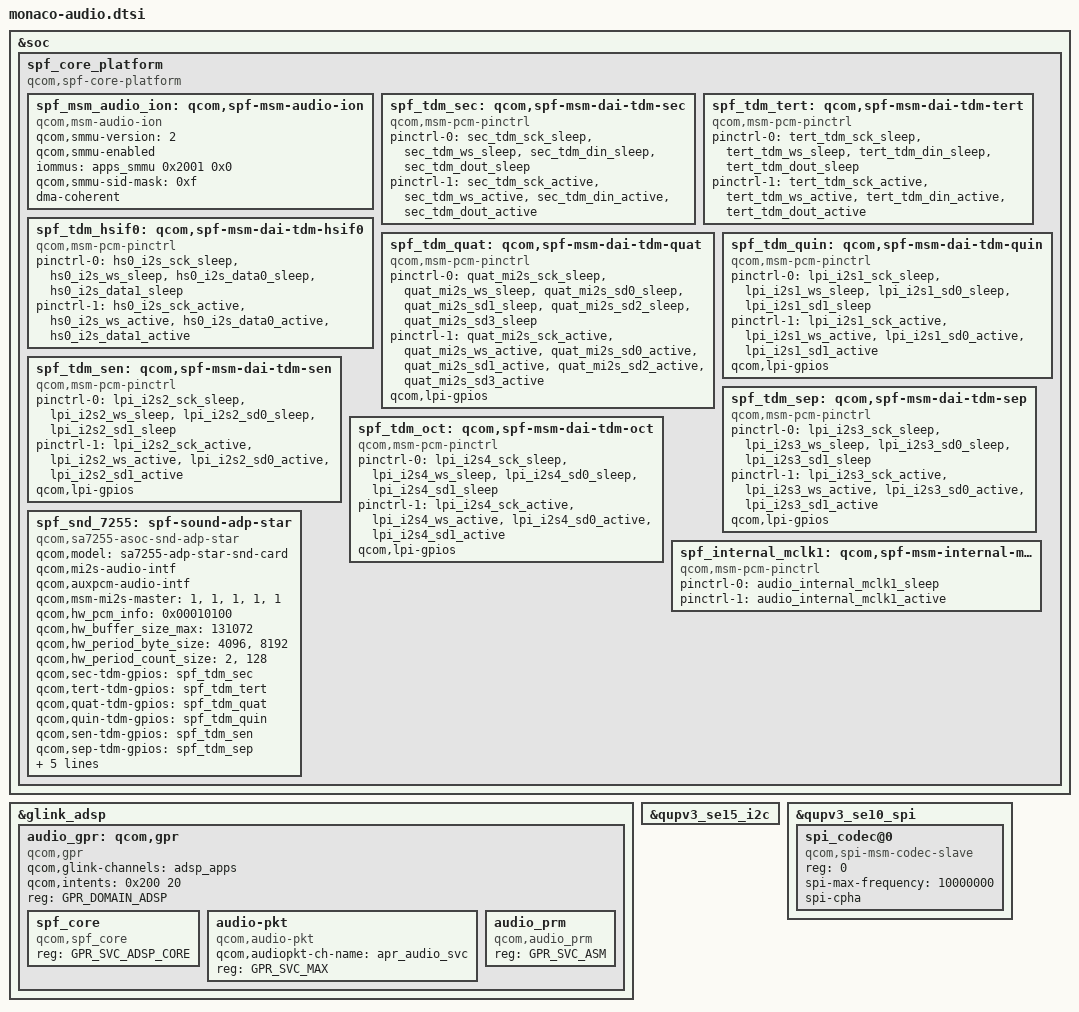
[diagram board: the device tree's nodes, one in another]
#include <bindings/qcom,audio-ext-clk.h>
#include <bindings/qcom,gpr.h>
#include "msm-audio-lpass.dtsi"
#include "monaco-lpi.dtsi"

&soc {
	spf_core_platform: spf_core_platform {
		compatible = "qcom,spf-core-platform";
	};
};


&glink_adsp {
	audio_gpr: qcom,gpr {
		compatible = "qcom,gpr";
		qcom,glink-channels = "adsp_apps";
		qcom,intents = <0x200 20>;
		reg = <GPR_DOMAIN_ADSP>;

		spf_core {
			compatible = "qcom,spf_core";
			reg = <GPR_SVC_ADSP_CORE>;
		};

		audio-pkt {
			compatible = "qcom,audio-pkt";
			qcom,audiopkt-ch-name = "apr_audio_svc";
			reg = <GPR_SVC_MAX>;
		};

		audio_prm {
			compatible = "qcom,audio_prm";
			reg = <GPR_SVC_ASM>;
		};
	};
};


&spf_core_platform {
	spf_msm_audio_ion: qcom,spf-msm-audio-ion {
		compatible = "qcom,msm-audio-ion";
		qcom,smmu-version = <2>;
		qcom,smmu-enabled;
		iommus = <&apps_smmu 0x2001 0x0>;
		qcom,smmu-sid-mask = /bits/ 64 <0xf>;
		dma-coherent;
	};

	spf_tdm_sec: qcom,spf-msm-dai-tdm-sec {
		compatible = "qcom,msm-pcm-pinctrl";
		pinctrl-names = "default", "active";
		pinctrl-0 = <&sec_tdm_sck_sleep &sec_tdm_ws_sleep
			&sec_tdm_din_sleep &sec_tdm_dout_sleep>;
		pinctrl-1 = <&sec_tdm_sck_active &sec_tdm_ws_active
			&sec_tdm_din_active &sec_tdm_dout_active>;
		#gpio-cells = <0>;
	};

	spf_tdm_tert: qcom,spf-msm-dai-tdm-tert {
		compatible = "qcom,msm-pcm-pinctrl";
		pinctrl-names = "default", "active";
		pinctrl-0 = <&tert_tdm_sck_sleep &tert_tdm_ws_sleep
			&tert_tdm_din_sleep &tert_tdm_dout_sleep>;
		pinctrl-1 = <&tert_tdm_sck_active &tert_tdm_ws_active
			&tert_tdm_din_active &tert_tdm_dout_active>;
		#gpio-cells = <0>;
	};

	spf_tdm_hsif0: qcom,spf-msm-dai-tdm-hsif0 {
		compatible = "qcom,msm-pcm-pinctrl";
		pinctrl-names = "default", "active";
		pinctrl-0 = <&hs0_i2s_sck_sleep &hs0_i2s_ws_sleep
			&hs0_i2s_data0_sleep &hs0_i2s_data1_sleep>;
		pinctrl-1 = <&hs0_i2s_sck_active &hs0_i2s_ws_active
			&hs0_i2s_data0_active &hs0_i2s_data1_active>;
		#gpio-cells = <0>;
	};

	spf_tdm_quat: qcom,spf-msm-dai-tdm-quat {
		compatible = "qcom,msm-pcm-pinctrl";
		pinctrl-names = "default", "active";
		pinctrl-0 = <&quat_mi2s_sck_sleep &quat_mi2s_ws_sleep
			&quat_mi2s_sd0_sleep &quat_mi2s_sd1_sleep
			&quat_mi2s_sd2_sleep &quat_mi2s_sd3_sleep>;
		pinctrl-1 = <&quat_mi2s_sck_active &quat_mi2s_ws_active
			&quat_mi2s_sd0_active &quat_mi2s_sd1_active
			&quat_mi2s_sd2_active &quat_mi2s_sd3_active>;
		qcom,lpi-gpios;
		#gpio-cells = <0>;
	};

	spf_tdm_quin: qcom,spf-msm-dai-tdm-quin {
		compatible = "qcom,msm-pcm-pinctrl";
		pinctrl-names = "default", "active";
		pinctrl-0 = <&lpi_i2s1_sck_sleep &lpi_i2s1_ws_sleep
			&lpi_i2s1_sd0_sleep &lpi_i2s1_sd1_sleep>;
		pinctrl-1 = <&lpi_i2s1_sck_active &lpi_i2s1_ws_active
			&lpi_i2s1_sd0_active &lpi_i2s1_sd1_active>;
		qcom,lpi-gpios;
		#gpio-cells = <0>;
	};

	spf_tdm_sen: qcom,spf-msm-dai-tdm-sen {
		compatible = "qcom,msm-pcm-pinctrl";
		pinctrl-names = "default", "active";
		pinctrl-0 = <&lpi_i2s2_sck_sleep &lpi_i2s2_ws_sleep
			&lpi_i2s2_sd0_sleep &lpi_i2s2_sd1_sleep>;
		pinctrl-1 = <&lpi_i2s2_sck_active &lpi_i2s2_ws_active
			&lpi_i2s2_sd0_active &lpi_i2s2_sd1_active>;
		qcom,lpi-gpios;
		#gpio-cells = <0>;
	};

	spf_tdm_sep: qcom,spf-msm-dai-tdm-sep {
		compatible = "qcom,msm-pcm-pinctrl";
		pinctrl-names = "default", "active";
		pinctrl-0 = <&lpi_i2s3_sck_sleep &lpi_i2s3_ws_sleep
			&lpi_i2s3_sd0_sleep &lpi_i2s3_sd1_sleep>;
		pinctrl-1 = <&lpi_i2s3_sck_active &lpi_i2s3_ws_active
			&lpi_i2s3_sd0_active &lpi_i2s3_sd1_active>;
		qcom,lpi-gpios;
		#gpio-cells = <0>;
	};

	spf_tdm_oct: qcom,spf-msm-dai-tdm-oct {
		compatible = "qcom,msm-pcm-pinctrl";
		pinctrl-names = "default", "active";
		pinctrl-0 = <&lpi_i2s4_sck_sleep &lpi_i2s4_ws_sleep
			&lpi_i2s4_sd0_sleep &lpi_i2s4_sd1_sleep>;
		pinctrl-1 = <&lpi_i2s4_sck_active &lpi_i2s4_ws_active
			&lpi_i2s4_sd0_active &lpi_i2s4_sd1_active>;
		qcom,lpi-gpios;
		#gpio-cells = <0>;
	};

	spf_internal_mclk1: qcom,spf-msm-internal-mclk1 {
		compatible = "qcom,msm-pcm-pinctrl";
		pinctrl-names = "default", "active";
		pinctrl-0 = <&audio_internal_mclk1_sleep>;
		pinctrl-1 = <&audio_internal_mclk1_active>;
		#gpio-cells = <0>;
	};

	spf_snd_7255: spf-sound-adp-star {
		compatible = "qcom,sa7255-asoc-snd-adp-star";
		qcom,model = "sa7255-adp-star-snd-card";
		qcom,mi2s-audio-intf;
		qcom,auxpcm-audio-intf;
		qcom,msm-mi2s-master = <1>, <1>, <1>, <1>, <1>;
		qcom,hw_pcm_info = <0x00010100>;
		qcom,hw_buffer_size_max = <131072>;
		qcom,hw_period_byte_size = <4096>, <8192>;
		qcom,hw_period_count_size = <2>, <128>;

		qcom,sec-tdm-gpios = <&spf_tdm_sec>;
		qcom,tert-tdm-gpios = <&spf_tdm_tert>;
		qcom,quat-tdm-gpios = <&spf_tdm_quat>;
		qcom,quin-tdm-gpios = <&spf_tdm_quin>;
		qcom,sen-tdm-gpios = <&spf_tdm_sen>;
		qcom,sep-tdm-gpios = <&spf_tdm_sep>;
		qcom,oct-tdm-gpios = <&spf_tdm_oct>;
		qcom,hsif0-tdm-gpios = <&spf_tdm_hsif0>;
		qcom,internal-mclk1-gpios = <&spf_internal_mclk1>;

		asoc-codec = <&stub_codec>;
		asoc-codec-names = "msm-stub-codec.1";
	};
};

&qupv3_se15_i2c {
	status = "ok";
};

&qupv3_se10_spi {
	status = "ok";
	spi_codec@0 {
		compatible = "qcom,spi-msm-codec-slave";
		reg = <0>;
		spi-max-frequency = <10000000>;
		spi-cpha;
	};
};
